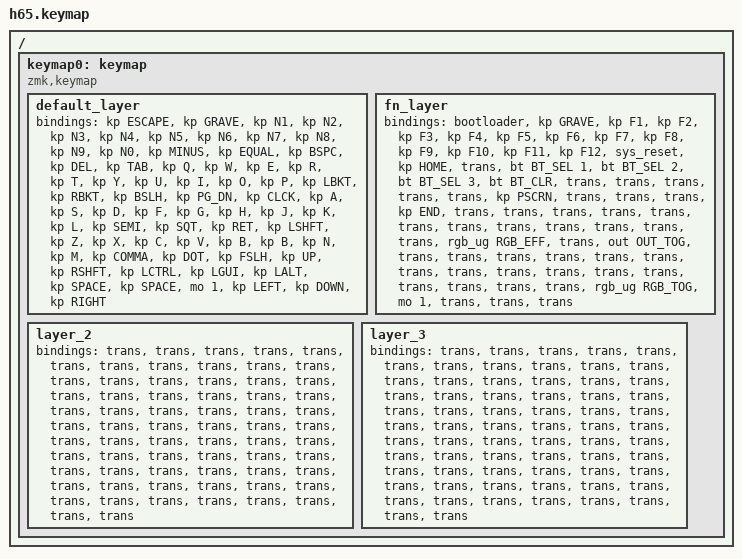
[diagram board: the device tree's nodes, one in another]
/*
 * Copyright (c) 2020 The ZMK Contributors
 *
 * SPDX-License-Identifier: MIT
 */

#include <behaviors.dtsi>
#include <dt-bindings/zmk/bt.h>
#include <dt-bindings/zmk/keys.h>
#include <dt-bindings/zmk/outputs.h>
#include <dt-bindings/zmk/rgb.h>

/ {
    keymap0: keymap {
        compatible = "zmk,keymap";

        default_layer {
            bindings = <
&kp ESCAPE  &kp GRAVE  &kp N1  &kp N2  &kp N3  &kp N4  &kp N5  &kp N6  &kp N7  &kp N8  &kp N9  &kp N0  &kp MINUS  &kp EQUAL  &kp BSPC  &kp DEL  &kp TAB  &kp Q  &kp W  &kp E  &kp R  &kp T  &kp Y  &kp U  &kp I  &kp O  &kp P  &kp LBKT  &kp RBKT  &kp BSLH  &kp PG_DN  &kp CLCK  &kp A  &kp S  &kp D  &kp F  &kp G  &kp H  &kp J  &kp K  &kp L  &kp SEMI  &kp SQT  &kp RET  &kp LSHFT  &kp Z  &kp X  &kp C  &kp V  &kp B  &kp B  &kp N  &kp M  &kp COMMA  &kp DOT  &kp FSLH  &kp UP  &kp RSHFT  &kp LCTRL  &kp LGUI  &kp LALT  &kp SPACE  &kp SPACE  &mo 1  &kp LEFT  &kp DOWN  &kp RIGHT
            >;
        };

        fn_layer {
            bindings = <
&bootloader  &kp GRAVE  &kp F1  &kp F2  &kp F3  &kp F4  &kp F5  &kp F6  &kp F7  &kp F8  &kp F9  &kp F10  &kp F11  &kp F12  &sys_reset  &kp HOME  &trans  &bt BT_SEL 1  &bt BT_SEL 2  &bt BT_SEL 3  &bt BT_CLR  &trans  &trans  &trans  &trans  &trans  &kp PSCRN  &trans  &trans  &trans  &kp END  &trans  &trans  &trans  &trans  &trans  &trans  &trans  &trans  &trans  &trans  &trans  &trans  &rgb_ug RGB_EFF  &trans  &out OUT_TOG  &trans  &trans  &trans  &trans  &trans  &trans  &trans  &trans  &trans  &trans  &trans  &trans  &trans  &trans  &trans  &trans  &rgb_ug RGB_TOG  &mo 1  &trans  &trans  &trans
            >;
        };

        layer_2 {
            bindings = <
&trans  &trans  &trans  &trans  &trans  &trans  &trans  &trans  &trans  &trans  &trans  &trans  &trans  &trans  &trans  &trans  &trans  &trans  &trans  &trans  &trans  &trans  &trans  &trans  &trans  &trans  &trans  &trans  &trans  &trans  &trans  &trans  &trans  &trans  &trans  &trans  &trans  &trans  &trans  &trans  &trans  &trans  &trans  &trans  &trans  &trans  &trans  &trans  &trans  &trans  &trans  &trans  &trans  &trans  &trans  &trans  &trans  &trans  &trans  &trans  &trans  &trans  &trans  &trans  &trans  &trans  &trans
            >;
        };

        layer_3 {
            bindings = <
&trans  &trans  &trans  &trans  &trans  &trans  &trans  &trans  &trans  &trans  &trans  &trans  &trans  &trans  &trans  &trans  &trans  &trans  &trans  &trans  &trans  &trans  &trans  &trans  &trans  &trans  &trans  &trans  &trans  &trans  &trans  &trans  &trans  &trans  &trans  &trans  &trans  &trans  &trans  &trans  &trans  &trans  &trans  &trans  &trans  &trans  &trans  &trans  &trans  &trans  &trans  &trans  &trans  &trans  &trans  &trans  &trans  &trans  &trans  &trans  &trans  &trans  &trans  &trans  &trans  &trans  &trans
            >;
        };
    };
};
